VERSION ""

NS_ :

BS_:

BU_:

BO_ 256 EngineData: 8 Vector__XXX
 SG_ EngineTemperature : 31|8@1+ (1,0) [-40.0|215.0] "Celsius" Vector__XXX
 SG_ EngineSpeed m0 : 15|16@1- (0.125,0.0) [0.0|8000.0] "rpm" Vector__XXX
 SG_ EngineDataMux M : 7|8@1+ (1,0) [0.0|8000.0] "rpm" Vector__XXX

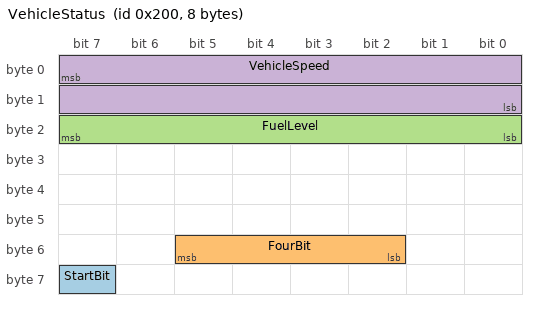
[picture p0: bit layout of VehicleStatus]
BO_ 512 VehicleStatus: 8 Vector__XXX
 SG_ StartBit : 63|1@0+ (0.4,0.0) [0.0|100.0] "%" Vector__XXX
 SG_ FourBit : 53|4@0+ (0.4,0.0) [0.0|100.0] "%" Vector__XXX
 SG_ FuelLevel : 23|8@0+ (0.4,0.0) [0.0|100.0] "%" Vector__XXX
 SG_ VehicleSpeed : 7|16@0+ (0.1,0.0) [0.0|300.0] "kph" Vector__XXX

BA_DEF_ BO_  "GenMsgCycleTime" INT 0 65535;
BA_DEF_DEF_  "GenMsgCycleTime" 0;
BA_ "GenMsgCycleTime" BO_ 256 100;
BA_ "GenMsgCycleTime" BO_ 512 100;
